VERSION ""

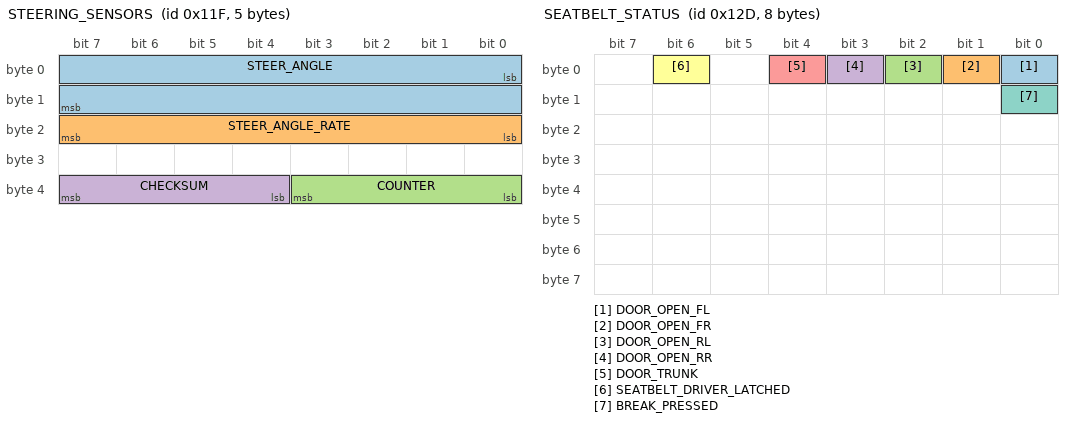
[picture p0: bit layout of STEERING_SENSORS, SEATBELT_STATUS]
BO_ 287 STEERING_SENSORS: 5 EPS
 SG_ STEER_ANGLE : 0|16@1- (0.1,0) [-650|650] "deg" EON
 SG_ STEER_ANGLE_RATE : 16|8@1- (1,0) [-650|650] "deg/s" EON
 SG_ COUNTER : 32|4@1+ (1,0) [0|255] "" EON
 SG_ CHECKSUM : 36|4@1+ (1,0) [0|255] "" EON
BO_ 523 LIGHT: 8 BDY
 SG_ LIGHT : 24|4@1+ (1,0) [0|16] "" EON
BO_ 301 SEATBELT_STATUS: 8 BDY
 SG_ DOOR_OPEN_FL : 0|1@0+ (1,0) [0|1] "" EON
 SG_ DOOR_OPEN_FR : 1|1@0+ (1,0) [0|1] "" EON
 SG_ DOOR_OPEN_RL : 2|1@0+ (1,0) [0|1] "" EON
 SG_ DOOR_OPEN_RR : 3|1@0+ (1,0) [0|1] "" EON
 SG_ DOOR_TRUNK : 4|1@0+ (1,0) [0|1] "" EON
 SG_ SEATBELT_DRIVER_LATCHED : 6|1@0+ (1,0) [0|1] "" EON
 SG_ BREAK_PRESSED : 8|1@0+ (1,0) [0|1] "" EON
BO_ 578 ENGINE_DATA: 8 BDY
 SG_ XMISSION_SPEED : 0|16@1+ (0.017,-510) [0|255] "" EON
 SG_ WHEEL_SPEED_FL : 0|16@1+ (0.017,-510) [0|255] "" EON
 SG_ WHEEL_SPEED_FR : 0|16@1+ (0.017,-510) [0|255] "" EON
 SG_ WHEEL_SPEED_RL : 0|16@1+ (0.017,-510) [0|255] "" EON
 SG_ WHEEL_SPEED_RR : 0|16@1+ (0.017,-510) [0|255] "" EON
BO_ 530 GEARBOX: 8 BDY
 SG_ GEAR_SHIFTER : 15|8@0+ (1,0) [0|255] "" EON
 SG_ GEAR : 15|8@0+ (1,0) [0|255] "" EON
 SG_ BREAK_P2 : 31|8@0+ (1,0) [0|255] "" EON
BO_ 269 POWERTRAIN: 8 BDY
 SG_ BREAK_P3 : 55|16@0+ (1,0) [67|71] "" EON  75 half
 SG_ ENGINE_RPM_UNKNOWN : 0|16@1- (0.25,0) [0|255] "" EON
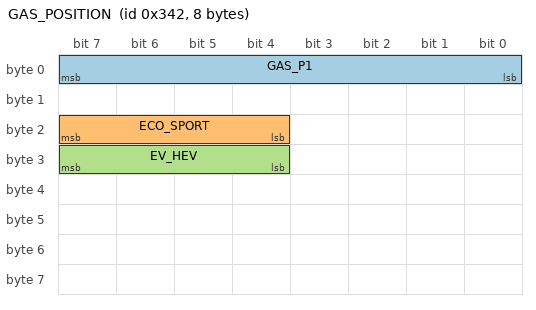
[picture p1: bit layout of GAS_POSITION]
BO_ 834 GAS_POSITION: 8 BDY
 SG_ GAS_P1 : 7|8@0+ (1,0) [0|255] "" EON
 SG_ ECO_SPORT : 20|4@1+ (1,0) [0|255] "" EON
 SG_ EV_HEV : 28|4@1+ (1,0) [0|255] "" EON

BO_ 548 BREAK_POSITION: 8 BDY
 SG_ BREAK_P4 : 32|16@1+ (1,0) [0|255] "" EON   9C-BC
BO_ 549 BREAK_POSITION2: 8 BDY
 SG_ BREAK_P5 : 24|16@1+ (1,0) [0|255] "" EON

BO_ 860 GEAR2_STATUS: 8 BDY
 SG_ GEAR2 : 15|8@0+ (1,0) [0|255] "" EON
BO_ 665 STEERING_KEY: 8 EPS
 SG_ STEER_KEY : 20|4@1- (1,0) [0|255] "" EON
VAL_ 530 GEAR_SHIFTER 4 "D" 3 "N" 2 "R" 1 "P" ;
VAL_ 530 BREAK_P2 8 "release" 12 "press" ;
VAL_ 860 GEAR2 4 "D" 3 "N" 2 "R" 1 "P" ;
VAL_ 269 BREAK_P3 67 "release" 71 "press" 75 "half" ;
VAL_ 834 ECO_SPORT 2 "sport" 1 "eco" ;
VAL_ 834 EV_HEV 9 "EV" 11 "HEV" ;
VAL_ 523 LIGHT 15 "OFF" 12 "AUTO" 9 "AUTO" 7 "NIGHT" 6 "LONG" 4 "LONG" 5 "LONG" ;
VAL_ 665 STEER_KEY 6 "LEFT" 7 "RIGHT"
